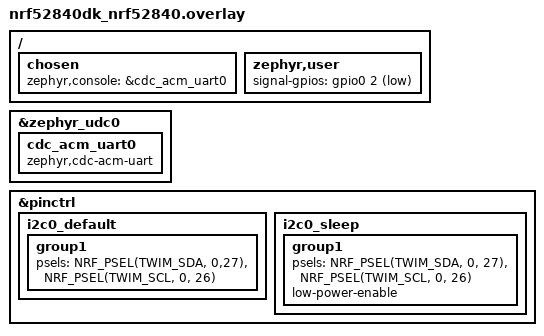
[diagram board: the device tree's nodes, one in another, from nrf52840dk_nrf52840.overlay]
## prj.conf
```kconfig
CONFIG_USB_DEVICE_STACK=y
CONFIG_USB_DEVICE_PRODUCT="Zephyr USB console sample"

CONFIG_SERIAL=y
CONFIG_CONSOLE=y
CONFIG_UART_CONSOLE=y
CONFIG_UART_LINE_CTRL=y

CONFIG_STDOUT_CONSOLE=y
CONFIG_LOG=n
CONFIG_I2C=y
CONFIG_ASSERT=y
```

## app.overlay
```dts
/*
 * Copyright (c) 2021 Nordic Semiconductor ASA
 *
 * SPDX-License-Identifier: Apache-2.0
 */

/ {
	chosen {
		zephyr,console = &cdc_acm_uart0;
	};
};

&zephyr_udc0 {
	cdc_acm_uart0: cdc_acm_uart0 {
		compatible = "zephyr,cdc-acm-uart";
	};
};

&pinctrl {
	i2c0_default: i2c0_default {
		group1 {
			psels = <NRF_PSEL(TWIM_SDA, 0,27)>,
				<NRF_PSEL(TWIM_SCL, 0, 26)>;
		};
	};

	i2c0_sleep: i2c0_sleep {
		group1 {
			psels = <NRF_PSEL(TWIM_SDA, 0, 27)>,
				<NRF_PSEL(TWIM_SCL, 0, 26)>;
			low-power-enable;
		};
	};
};
```

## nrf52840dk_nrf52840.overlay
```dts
// To get started, press Ctrl+Space to bring up the completion menu and view the available nodes.

// You can also use the buttons in the sidebar to perform actions on nodes.
// Actions currently available include:

// * Enabling / disabling the node
// * Adding the bus to a bus
// * Removing the node
// * Connecting ADC channels

// For more help, browse the DeviceTree documentation at https://docs.zephyrproject.org/latest/guides/dts/index.html
// You can also visit the nRF DeviceTree extension documentation at https://nrfconnect.github.io/vscode-nrf-connect/devicetree/nrfdevicetree.html
/*
 * Copyright (c) 2021 Nordic Semiconductor ASA
 *
 * SPDX-License-Identifier: Apache-2.0
 */


 


 / {
	chosen {
		zephyr,console = &cdc_acm_uart0;
	};
	zephyr,user {
        signal-gpios = <&gpio0 2 (GPIO_PULL_UP | GPIO_ACTIVE_LOW)>;
    };
};

&zephyr_udc0 {
	cdc_acm_uart0: cdc_acm_uart0 {
		compatible = "zephyr,cdc-acm-uart";
	};
};


&pinctrl {
	i2c0_default: i2c0_default {
		group1 {
			psels = <NRF_PSEL(TWIM_SDA, 0,27)>,
				<NRF_PSEL(TWIM_SCL, 0, 26)>;
		};
	};

	i2c0_sleep: i2c0_sleep {
		group1 {
			psels = <NRF_PSEL(TWIM_SDA, 0, 27)>,
				<NRF_PSEL(TWIM_SCL, 0, 26)>;
			low-power-enable;
		};
	};


};
```

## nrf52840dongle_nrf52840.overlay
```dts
// To get started, press Ctrl+Space to bring up the completion menu and view the available nodes.

// You can also use the buttons in the sidebar to perform actions on nodes.
// Actions currently available include:

// * Enabling / disabling the node
// * Adding the bus to a bus
// * Removing the node
// * Connecting ADC channels

// For more help, browse the DeviceTree documentation at https://docs.zephyrproject.org/latest/guides/dts/index.html
// You can also visit the nRF DeviceTree extension documentation at https://nrfconnect.github.io/vscode-nrf-connect/devicetree/nrfdevicetree.html
// To get started, press Ctrl+Space to bring up the completion menu and view the available nodes.

// You can also use the buttons in the sidebar to perform actions on nodes.
// Actions currently available include:

// * Enabling / disabling the node
// * Adding the bus to a bus
// * Removing the node
// * Connecting ADC channels

// For more help, browse the DeviceTree documentation at https://docs.zephyrproject.org/latest/guides/dts/index.html
// You can also visit the nRF DeviceTree extension documentation at https://nrfconnect.github.io/vscode-nrf-connect/devicetree/nrfdevicetree.html
/*
 * Copyright (c) 2021 Nordic Semiconductor ASA
 *
 * SPDX-License-Identifier: Apache-2.0
 */

 / {
	chosen {
		zephyr,console = &cdc_acm_uart0;
	};
	zephyr,user {
        signal-gpios = <&gpio0 20 (GPIO_PULL_UP | GPIO_ACTIVE_LOW)>;
    };
};

&zephyr_udc0 {
	cdc_acm_uart0: cdc_acm_uart0 {
		compatible = "zephyr,cdc-acm-uart";
	};
};

&pinctrl {
	i2c0_default: i2c0_default {
		group1 {
			psels = <NRF_PSEL(TWIM_SDA, 0,29)>,
				<NRF_PSEL(TWIM_SCL, 0, 31)>;
		};
	};

	i2c0_sleep: i2c0_sleep {
		group1 {
			psels = <NRF_PSEL(TWIM_SDA, 0, 29)>,
				<NRF_PSEL(TWIM_SCL, 0, 31)>;
			low-power-enable;
		};
	};
};
```

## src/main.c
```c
#include <zephyr.h>
#include <zephyr/sys/printk.h>
#include <zephyr/usb/usb_device.h>
#include <zephyr/drivers/uart.h>
#include <stdio.h>
#include <logging/log.h>
#include "max30102.h"

#define ZEPHYR_USER_NODE DT_PATH(zephyr_user)

BUILD_ASSERT(DT_NODE_HAS_COMPAT(DT_CHOSEN(zephyr_console), zephyr_cdc_acm_uart),
	     "Console device is not ACM CDC UART device");

LOG_MODULE_REGISTER(MAIN, CONFIG_LOG_DEFAULT_LEVEL);

K_FIFO_DEFINE(ppg_items);
K_SEM_DEFINE(sem_initialized_max30102, 0, 1);
K_SEM_DEFINE(sem_interruptmax30102, 0, 1);

static struct gpio_callback interrupt_max30102;
static const struct gpio_dt_spec signal = GPIO_DT_SPEC_GET(ZEPHYR_USER_NODE, signal_gpios);

typedef struct { 
    void *fifo_reserved;   /* 1st word reserved for use by FIFO */
    uint32_t ppgvalueRed;
	uint32_t ppgvalueIr;
} fifo_item_t;

void max30102isr(const struct device *dev, struct gpio_callback *cb, uint32_t pins) {	
	k_sem_give(&sem_interruptmax30102);		
}

void attachinterrupt(void) {
	
	__ASSERT(device_is_ready(signal.port), "custom device not ready");
	gpio_pin_configure_dt(&signal, GPIO_INPUT);
	gpio_pin_interrupt_configure_dt(&signal, GPIO_INT_EDGE_TO_ACTIVE);
	gpio_init_callback(&interrupt_max30102, max30102isr, BIT(signal.pin));
	gpio_add_callback(signal.port, &interrupt_max30102);	
}

void main(void)
{	
	const struct device *dev = DEVICE_DT_GET(DT_CHOSEN(zephyr_console));
	uint32_t dtr = 0;

	if (usb_enable(NULL)) {
		return;
	}

	/* Poll if the DTR flag was set */
	while (!dtr) {
		uart_line_ctrl_get(dev, UART_LINE_CTRL_DTR, &dtr);
		/* Give CPU resources to low priority threads. */
		k_sleep(K_MSEC(100));
	}

	
	if(max30102_init()) {
		LOG_ERR("could not initialize");
		k_sleep(K_FOREVER);		
	}	
	attachinterrupt();
	uint8_t max_read_state = max30102_interrupt_state(); //clear interrupt;

	LOG_INF("max initialized, read state:%i", max_read_state);
	
	k_sem_give(&sem_initialized_max30102);
	
	for(;;) {
		fifo_item_t *queued;
		queued = k_fifo_get(&ppg_items, K_FOREVER);
		#if (led_channels > 1)
			printk("%d,%d\n", queued->ppgvalueIr, queued->ppgvalueRed);
		#else
			printk("%d\n", queued->ppgvalueIr);
		#endif

	}
}


void max30102read(void) {	
	k_sem_take(&sem_initialized_max30102, K_FOREVER);
	
	uint8_t amount_samples;
	uint8_t isrstate;
	ppg_item_t buffer[32]; //maximum amount for ic
	while (1) {		
		k_sem_take(&sem_interruptmax30102, K_MSEC(5000));
		isrstate = max30102_interrupt_state();
		if (isrstate != 0b10000000) {
			LOG_WRN("unexpected max30102int: %d", isrstate);			
		} 
		amount_samples = GetSamplesAvailable();		
		
		max30102data(buffer, amount_samples);
		
		for (int i = 0; i < amount_samples; i++)
		{
			fifo_item_t toqueue = {.ppgvalueIr = buffer[i].ir, .ppgvalueRed = buffer[i].red};			
			k_fifo_put(&ppg_items, &toqueue);
		} 			
	}
}

K_THREAD_DEFINE(max30102_read_thread_id, 1024, max30102read, NULL, NULL,
		NULL, 7, 0, 0);
```

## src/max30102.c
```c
/*
 * Copyright (c) 2017, NXP
 *
 * SPDX-License-Identifier: Apache-2.0
 */
//#define DT_DRV_COMPAT maxim_max30101

#include <zephyr.h>
#include <stdio.h>
#include <logging/log.h>
#include "max30102.h"

#define register_count 9
#define led_channels 1

const struct device *i2c;


max30102_config max30102cfg = {
// 	.i2c_label = DT_INST_PROP(0, label),
 	.i2c_addr = 0x57// DT_INST_REG_ADDR(0),
};



LOG_MODULE_REGISTER(MAX30102, 0);

int GetSamplesAvailable()
{
	uint8_t fifo_wr_ptr;
	uint8_t fifo_rd_ptr;
	int samples_avalable = 0;

	int wr = i2c_reg_read_byte(i2c, max30102cfg.i2c_addr, 0x04, &fifo_wr_ptr);
	int rd = i2c_reg_read_byte(i2c, max30102cfg.i2c_addr, 0x06, &fifo_rd_ptr);
	if(wr || rd) {
		LOG_ERR("max30102 read or write pointer error");
		return 0;
	}

	if (fifo_wr_ptr != fifo_rd_ptr)
	{
		samples_avalable = fifo_wr_ptr - fifo_rd_ptr;
		if (samples_avalable < 0) {
			samples_avalable += 32; // wrap condition>		
		}
	}	
	return samples_avalable;
}

float temperature(void)
{
	uint8_t temperature;
	uint8_t fraction;
	i2c_reg_read_byte(i2c, max30102cfg.i2c_addr, 0x1F, &temperature);
	i2c_reg_read_byte(i2c, max30102cfg.i2c_addr, 0x20, &fraction);
	if (temperature > 0x7F)
	{
		temperature = -0xFF + (temperature - 1);
	}
	// enable temperature
	i2c_reg_write_byte(i2c, max30102cfg.i2c_addr, 0x21, 1);
	return (float)temperature + fraction * 0.0625;
}


int fetch_max30102(uint32_t * samplebuffer, int samplesToTake)
{
	if (samplesToTake == 0) return 0;	
	
	uint32_t fifo_data;
	int num_bytes = 3 * led_channels * samplesToTake; //2 channels, 3 bytes each
	uint8_t buffer[num_bytes];

	/* Read all the active channels for all samples */		 
	if (i2c_burst_read(i2c, max30102cfg.i2c_addr, 0x07, buffer, num_bytes))
	{
		LOG_ERR("could not read sample");
		return 1;
	}
	
	for (uint32_t y = 0; y < (samplesToTake * led_channels); y++)
	{				
		/* Each channel sample is 18-bits */
		fifo_data = (buffer[y*3] << 16) | (buffer[y*3 + 1] << 8) |
					(buffer[y*3 + 2]);
		fifo_data &= MAX30102_FIFO_DATA_MASK;

		samplebuffer[y] = fifo_data;
	}

	return 0;
}

int max30102data(ppg_item_t * ppg_items, int samplesToTake) {
	int buffersize = samplesToTake * 2;
	uint32_t buffer[buffersize]; //two led colors
	if(fetch_max30102(buffer, samplesToTake)){
		return 1;
	}
	unsigned int pic = 0; //ppg item count
	for (size_t i = 0; i < buffersize; i+=led_channels)
	{				
		ppg_items[pic].ir = buffer[i];
#if(led_channels > 1)
		ppg_items[pic].red = buffer[i+1];		
#endif
		pic++;
	}
	return 0;
}

uint8_t max30102_interrupt_state() {
	uint8_t status;
	i2c_reg_read_byte(i2c, max30102cfg.i2c_addr, 0x00, &status);
	return status;
}

int safewriteconfig(uint8_t reg, uint8_t value) {
	if (i2c_reg_write_byte(i2c, max30102cfg.i2c_addr, reg,value))
	{
		LOG_ERR("couldn't write to 0x%02x", reg);
		return -EIO;
	}
	return 0;
}

int max30102_init()
{
	uint8_t part_id;
	uint8_t mode_cfg;

	/* Get the I2C device */
	//i2c = device_get_binding(max30102cfg.i2c_label);
	i2c = DEVICE_DT_GET(DT_NODELABEL(i2c0));
	__ASSERT(device_is_ready(i2c), "max30102 device not ready");
	

	/* Check the part id to make sure this is MAX30102 */
	if (i2c_reg_read_byte(i2c, max30102cfg.i2c_addr,
						  MAX30102_REG_PART_ID, &part_id))
	{
		LOG_ERR("Could not get Part ID");
		return -EIO;
	}
	if (part_id != MAX30102_PART_ID)
	{
		LOG_ERR("Got Part ID 0x%02x, expected 0x%02x",
				part_id, MAX30102_PART_ID);
		return -EIO;
	}
	else
	{
		LOG_INF("Got Part ID 0x%02x as expected", part_id);
	}

	/* Reset the sensor */
	if (i2c_reg_write_byte(i2c, max30102cfg.i2c_addr,
						   MAX30102_REG_MODE_CFG,
						   MAX30102_MODE_CFG_RESET_MASK))
	{
		return -EIO;
	}

	/* Wait for reset to be cleared */
	do
	{
		if (i2c_reg_read_byte(i2c, max30102cfg.i2c_addr,
							  MAX30102_REG_MODE_CFG, &mode_cfg))
		{
			LOG_ERR("Could read mode cfg after reset");
			return -EIO;
		}
	} while (mode_cfg & MAX30102_MODE_CFG_RESET_MASK);
	
	uint8_t regsettings[register_count][2] = {
			//Interrupt Enable
			{0x02, 0b10000000},
			//DIE_TEMP_RDY_EN = false
			{0x03, 0b00000000},
			//FIFO config - average, yes rollover, fifo almost full @ 4 left	
			{0x08, 0b01011111},
			// mode configuration
			{0x09, 0b00000010},
			//Sample Rate Control
			{0x0A, 0b01110111},
			//LED pulse amplitude 
			{0x0C, 0x7f},  	//red
			{0x0D, 0x7f},	//ir
			//multi-LED mode control 
			{0x11, 0b00000010},
			{0x12, 0b00000000}
		};		
	
	for (size_t i = 0; i < register_count; i++)
	{		
		if(safewriteconfig(regsettings[i][0], regsettings[i][1])) {
			return -EIO;
		}
	}

	return 0;
}
```

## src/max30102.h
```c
/*
 * Copyright (c) 2017, NXP
 *
 * SPDX-License-Identifier: Apache-2.0
 */

#include <drivers/sensor.h>
#include <drivers/i2c.h>
#include <drivers/gpio.h>

#define MAX30102_REG_INT_STS1		0x00
#define MAX30102_REG_INT_STS2		0x01
#define MAX30102_REG_INT_EN1		0x02
#define MAX30102_REG_INT_EN2		0x03
#define MAX30102_REG_FIFO_WR		0x04
#define MAX30102_REG_FIFO_OVF		0x05
#define MAX30102_REG_FIFO_RD		0x06
#define MAX30102_REG_FIFO_DATA		0x07
#define MAX30102_REG_FIFO_CFG		0x08
#define MAX30102_REG_MODE_CFG		0x09
#define MAX30102_REG_SPO2_CFG		0x0a

#define MAX30102_REG_PILOT_PA		0x10

#define MAX30102_REG_TINT		0x1f
#define MAX30102_REG_TFRAC		0x20
#define MAX30102_REG_TEMP_CFG		0x21
#define MAX30102_REG_PROX_INT		0x30
#define MAX30102_REG_REV_ID		0xfe
#define MAX30102_REG_PART_ID		0xff

#define MAX30102_INT_PPG_MASK		(1 << 6)

#define MAX30102_FIFO_CFG_SMP_AVE_SHIFT		5
#define MAX30102_FIFO_CFG_FIFO_FULL_SHIFT	0
#define MAX30102_FIFO_CFG_ROLLOVER_EN_MASK	(1 << 4)

#define MAX30102_MODE_CFG_SHDN_MASK	(1 << 7)
#define MAX30102_MODE_CFG_RESET_MASK	(1 << 6)

#define MAX30102_SPO2_ADC_RGE_SHIFT	5
#define MAX30102_SPO2_SR_SHIFT		2
#define MAX30102_PART_ID		0x15

#define MAX30102_BYTES_PER_CHANNEL	3
#define MAX30102_MAX_NUM_CHANNELS	2
#define MAX30102_MAX_BYTES_PER_SAMPLE	(MAX30102_MAX_NUM_CHANNELS * MAX30102_BYTES_PER_CHANNEL)

#define MAX30102_SLOT_LED_MASK		0x03

#define MAX30102_FIFO_DATA_BITS		18
#define MAX30102_FIFO_DATA_MASK		((1 << MAX30102_FIFO_DATA_BITS) - 1)



typedef struct {
	uint32_t ir;
	uint32_t red;
} ppg_item_t;

enum max30102_mode {
	MAX30102_MODE_HEART_RATE	= 2,
	MAX30102_MODE_SPO2		= 3,
	MAX30102_MODE_MULTI_LED		= 7,
};

enum max30102_led_channel {
	MAX30102_LED_CHANNEL_RED	= 0,
	MAX30102_LED_CHANNEL_IR,
};

enum max30102_pw {
	MAX30102_PW_15BITS		= 0,
	MAX30102_PW_16BITS,
	MAX30102_PW_17BITS,
	MAX30102_PW_18BITS,
};

typedef struct {	
	const char *i2c_label;
	uint16_t i2c_addr;			
} max30102_config;


float temperature();
int max30102_init();
int GetSamplesAvailable();
int max30102data(ppg_item_t * ppg_items, int samplesToTake);
uint8_t max30102_interrupt_state();
```
